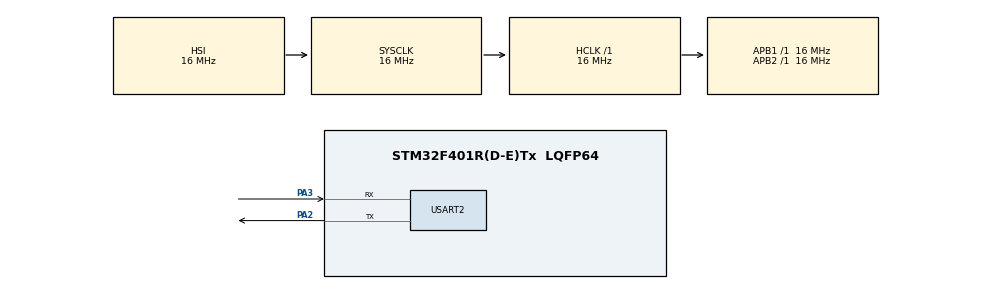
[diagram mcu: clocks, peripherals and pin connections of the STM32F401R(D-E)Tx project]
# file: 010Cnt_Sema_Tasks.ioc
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FREERTOS.Tasks01=defaultTask,24,128,StartDefaultTask,Default,NULL,Dynamic,NULL,NULL
Mcu.Family=STM32F4
Mcu.Name=STM32F401R(D-E)Tx
Mcu.Package=LQFP64
NVIC.PriorityGroup=NVIC_PRIORITYGROUP_4
NVIC.TIM5_IRQn=true\:15\:0\:false\:false\:true\:false\:false\:true\:true
NVIC.TimeBase=TIM5_IRQn
NVIC.TimeBaseIP=TIM5
PA13.Mode=Serial_Wire
PA13.Signal=SYS_JTMS-SWDIO
PA14.Mode=Serial_Wire
PA14.Signal=SYS_JTCK-SWCLK
PA2.Mode=Asynchronous
PA2.Signal=USART2_TX
PA3.Mode=Asynchronous
PA3.Signal=USART2_RX
ProjectManager.HeapSize=0x200
ProjectManager.StackSize=0x400
ProjectManager.TargetToolchain=STM32CubeIDE
RCC.AHBFreq_Value=16000000
RCC.APB1Freq_Value=16000000
RCC.APB2Freq_Value=16000000
RCC.CortexFreq_Value=16000000
RCC.HSE_VALUE=25000000
RCC.HSI_VALUE=16000000
RCC.LSE_VALUE=32768
RCC.SYSCLKFreq_VALUE=16000000
RCC.VCOOutputFreq_Value=192000000
USART2.VirtualMode=VM_ASYNC
VP_FREERTOS_VS_CMSIS_V2.Mode=CMSIS_V2
VP_SYS_VS_tim5.Mode=TIM5
board=custom

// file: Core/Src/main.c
/* USER CODE BEGIN Header */
/**
  ******************************************************************************
  * @file           : main.c
  * @brief          : Main program body - Counting Semaphore Demo
  ******************************************************************************
  * @attention
  *
  * Copyright (c) 2026 STMicroelectronics.
  * All rights reserved.
  *
  * This software is licensed under terms that can be found in the LICENSE file
  * in the root directory of this software component.
  * If no LICENSE file comes with this software, it is provided AS-IS.
  *
  ******************************************************************************
  */
/* USER CODE END Header */
#include "main.h"
#include "cmsis_os.h"

/* USER CODE BEGIN Includes */
#include <stdio.h>
#include <stdlib.h>
#include <string.h>

#include "FreeRTOS.h"
#include "task.h"
#include "queue.h"
#include "semphr.h"
#include "stream_buffer.h"
#include "SEGGER_SYSVIEW.h"
//#include "usart.h"   /* Declares extern UART_HandleTypeDef huart2 */
/* USER CODE END Includes */

/* USER CODE BEGIN PD */
#define MAX_EVENT_COUNT         10   /* Max value counting semaphore can hold */
#define INITIAL_EVENT_COUNT      0   /* Initial count at startup              */

#define LOGGER_TASK_PRIORITY     0   /* Lowest priority - handles UART log output */
#define HANDLER_TASK_PRIORITY    1   /* Lower priority                        */
#define PERIODIC_TASK_PRIORITY   3   /* Higher priority                       */

#define LOG_STREAM_BUFFER_SIZE   512
/* USER CODE END PD */

UART_HandleTypeDef huart2;

/* Definitions for defaultTask */
osThreadId_t defaultTaskHandle;
const osThreadAttr_t defaultTask_attributes = {
  .name = "defaultTask",
  .stack_size = 128 * 4,
  .priority = (osPriority_t) osPriorityNormal,
};
/* USER CODE BEGIN PV */
TaskHandle_t xHandlerTaskHandle  = NULL;
TaskHandle_t xPeriodicTaskHandle = NULL;
TaskHandle_t xLoggerTaskHandle   = NULL;

/* Counting semaphore used to latch events from the fast triggering interrupt */
SemaphoreHandle_t    xCountingSemaphore = NULL;

/* Lock-free stream buffer for thread-safe/ISR-safe logging */
StreamBufferHandle_t xLogStreamBuffer   = NULL;
/* USER CODE END PV */

void SystemClock_Config(void);
static void MX_GPIO_Init(void);
static void MX_USART2_UART_Init(void);
void StartDefaultTask(void *argument);

/* USER CODE BEGIN PFP */
void printmsg(const char *msg);
void printmsgFromISR(const char *msg);

static void Handler_task(void *pvParameters);
static void Periodic_task(void *pvParameters);
static void Logger_task(void *pvParameters);

static void prvSetupSoftwareInterrupt(void);
/* USER CODE END PFP */

/* USER CODE BEGIN 0 */

/**
 * @brief Thread-safe logging function for tasks.
 */
void printmsg(const char *msg)
{
    if (xLogStreamBuffer != NULL)
    {
        xStreamBufferSend(xLogStreamBuffer, msg, strlen(msg), portMAX_DELAY);
    }
}

/**
 * @brief Non-blocking, lock-free logging function for ISRs.
 */
void printmsgFromISR(const char *msg)
{
    BaseType_t xHigherPriorityTaskWoken = pdFALSE;
    if (xLogStreamBuffer != NULL)
    {
        xStreamBufferSendFromISR(xLogStreamBuffer, msg, strlen(msg), &xHigherPriorityTaskWoken);
        portEND_SWITCHING_ISR(xHigherPriorityTaskWoken);
    }
}

/**
 * @brief Software/button interrupt setup
 */
static void prvSetupSoftwareInterrupt(void)
{
    NVIC_SetPriority(EXTI15_10_IRQn, configLIBRARY_MAX_SYSCALL_INTERRUPT_PRIORITY);
    NVIC_EnableIRQ(EXTI15_10_IRQn);
}
/* USER CODE END 0 */

int main(void)
{

  /* MCU Configuration--------------------------------------------------------*/

  /* Reset of all peripherals, Initializes the Flash interface and the Systick. */
  HAL_Init();

  /* Configure the system clock */
  SystemClock_Config();

  /* Initialize all configured peripherals */
  MX_GPIO_Init();
  MX_USART2_UART_Init();
  /* USER CODE BEGIN 2 */
    CoreDebug->DEMCR |= (1 << 24);
    DWT->CYCCNT = 0;
    DWT->CTRL |= (1 << 0);

    SEGGER_SYSVIEW_Conf();
    SEGGER_SYSVIEW_Start();

    /* Create non-blocking Stream Buffer for thread-safe UART logging */
    xLogStreamBuffer = xStreamBufferCreate(LOG_STREAM_BUFFER_SIZE, 1);

    /* Create counting semaphore */
    xCountingSemaphore = xSemaphoreCreateCounting(MAX_EVENT_COUNT, INITIAL_EVENT_COUNT);

    if ((xCountingSemaphore != NULL) && (xLogStreamBuffer != NULL))
    {
        prvSetupSoftwareInterrupt();

        /* Create 'Logger' task (Priority 0) */
        xTaskCreate(Logger_task, "Logger", 256, NULL,
                    LOGGER_TASK_PRIORITY, &xLoggerTaskHandle);

        /* Create 'Handler' task (Priority 1) */
        xTaskCreate(Handler_task, "Handler", 256, NULL,
                    HANDLER_TASK_PRIORITY, &xHandlerTaskHandle);

        /* Create 'Periodic' task (Priority 3) */
        xTaskCreate(Periodic_task, "Periodic", 256, NULL,
                    PERIODIC_TASK_PRIORITY, &xPeriodicTaskHandle);

        printmsg("Demo of usage of counting semaphore with thread-safe logging\r\n");

        /* Start the FreeRTOS scheduler */
        vTaskStartScheduler();
    }
    else
    {
        /* Heap allocation failed */
    }

    /* Infinite loop if scheduler fails to start */
    for (;;);
  /* USER CODE END 2 */

  /* Init scheduler */
  osKernelInitialize();

  /* Create the thread(s) */
  /* creation of defaultTask */
  defaultTaskHandle = osThreadNew(StartDefaultTask, NULL, &defaultTask_attributes);

  /* Start scheduler */
  osKernelStart();

  /* We should never get here as control is now taken by the scheduler */

  /* Infinite loop */
  while (1)
  {

  }
}

void SystemClock_Config(void)
{
  RCC_OscInitTypeDef RCC_OscInitStruct = {0};
  RCC_ClkInitTypeDef RCC_ClkInitStruct = {0};

  /** Configure the main internal regulator output voltage
  */
  __HAL_RCC_PWR_CLK_ENABLE();
  __HAL_PWR_VOLTAGESCALING_CONFIG(PWR_REGULATOR_VOLTAGE_SCALE2);

  /** Initializes the RCC Oscillators according to the specified parameters
  * in the RCC_OscInitTypeDef structure.
  */
  RCC_OscInitStruct.OscillatorType = RCC_OSCILLATORTYPE_HSI;
  RCC_OscInitStruct.HSIState = RCC_HSI_ON;
  RCC_OscInitStruct.HSICalibrationValue = RCC_HSICALIBRATION_DEFAULT;
  RCC_OscInitStruct.PLL.PLLState = RCC_PLL_NONE;
  if (HAL_RCC_OscConfig(&RCC_OscInitStruct) != HAL_OK)
  {
    Error_Handler();
  }

  /** Initializes the CPU, AHB and APB buses clocks
  */
  RCC_ClkInitStruct.ClockType = RCC_CLOCKTYPE_HCLK|RCC_CLOCKTYPE_SYSCLK
                              |RCC_CLOCKTYPE_PCLK1|RCC_CLOCKTYPE_PCLK2;
  RCC_ClkInitStruct.SYSCLKSource = RCC_SYSCLKSOURCE_HSI;
  RCC_ClkInitStruct.AHBCLKDivider = RCC_SYSCLK_DIV1;
  RCC_ClkInitStruct.APB1CLKDivider = RCC_HCLK_DIV1;
  RCC_ClkInitStruct.APB2CLKDivider = RCC_HCLK_DIV1;

  if (HAL_RCC_ClockConfig(&RCC_ClkInitStruct, FLASH_LATENCY_0) != HAL_OK)
  {
    Error_Handler();
  }
}

static void MX_USART2_UART_Init(void)
{

  huart2.Instance = USART2;
  huart2.Init.BaudRate = 115200;
  huart2.Init.WordLength = UART_WORDLENGTH_8B;
  huart2.Init.StopBits = UART_STOPBITS_1;
  huart2.Init.Parity = UART_PARITY_NONE;
  huart2.Init.Mode = UART_MODE_TX_RX;
  huart2.Init.HwFlowCtl = UART_HWCONTROL_NONE;
  huart2.Init.OverSampling = UART_OVERSAMPLING_16;
  if (HAL_UART_Init(&huart2) != HAL_OK)
  {
    Error_Handler();
  }

}

static void MX_GPIO_Init(void)
{

  /* GPIO Ports Clock Enable */
  __HAL_RCC_GPIOA_CLK_ENABLE();

}

/* USER CODE BEGIN 4 */

/* ---------------- Logger Task ---------------- */
static void Logger_task(void *pvParameters)
{
    char rx_buf[64];
    size_t xReceivedBytes;

    for (;;)
    {
        xReceivedBytes = xStreamBufferReceive(xLogStreamBuffer,
                                             rx_buf,
                                             sizeof(rx_buf) - 1,
                                             portMAX_DELAY);
        if (xReceivedBytes > 0)
        {
            rx_buf[xReceivedBytes] = '\0';
            HAL_UART_Transmit(&huart2, (uint8_t*)rx_buf, xReceivedBytes, HAL_MAX_DELAY);
        }
    }
}

/* ---------------- Handler Task ---------------- */
static void Handler_task(void *pvParameters)
{
    char msg[64];

    for (;;)
    {
        /* Block until an event is latched by the semaphore */
        xSemaphoreTake(xCountingSemaphore, portMAX_DELAY);

        snprintf(msg, sizeof(msg), "Handler task - Processing event.\r\n");
        printmsg(msg);
    }
}

/* ---------------- Periodic Task ---------------- */
static void Periodic_task(void *pvParameters)
{
    char msg[64];

    for (;;)
    {
        vTaskDelay(pdMS_TO_TICKS(500));

        snprintf(msg, sizeof(msg), "Periodic task - Pending the interrupt.\r\n");
        printmsg(msg);

        /* Trigger software interrupt */
        NVIC_SetPendingIRQ(EXTI15_10_IRQn);

        snprintf(msg, sizeof(msg), "Periodic task - Resuming.\r\n");
        printmsg(msg);
    }
}

/* ---------------- Fast Triggering Interrupt (ISR) ---------------- */
void EXTI15_10_IRQHandler(void)
{
    BaseType_t xHigherPriorityTaskWoken = pdFALSE;

    printmsgFromISR("==>Button_Handler\r\n");

    /* Increment counting semaphore multiple times to simulate burst events */
    xSemaphoreGiveFromISR(xCountingSemaphore, &xHigherPriorityTaskWoken);
    xSemaphoreGiveFromISR(xCountingSemaphore, &xHigherPriorityTaskWoken);
    xSemaphoreGiveFromISR(xCountingSemaphore, &xHigherPriorityTaskWoken);
    xSemaphoreGiveFromISR(xCountingSemaphore, &xHigherPriorityTaskWoken);
    xSemaphoreGiveFromISR(xCountingSemaphore, &xHigherPriorityTaskWoken);

    NVIC_ClearPendingIRQ(EXTI15_10_IRQn);

    portEND_SWITCHING_ISR(xHigherPriorityTaskWoken);
}

/* USER CODE END 4 */

void StartDefaultTask(void *argument)
{
  for(;;)
  {
    osDelay(1);
  }
}

void HAL_TIM_PeriodElapsedCallback(TIM_HandleTypeDef *htim)
{
  if (htim->Instance == TIM5)
  {
    HAL_IncTick();
  }
}

void Error_Handler(void)
{
  __disable_irq();
  while (1)
  {
  }
}
